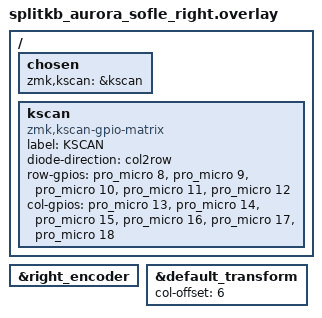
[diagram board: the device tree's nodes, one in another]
/*
 * Copyright (c) 2023 The ZMK Contributors
 *
 * SPDX-License-Identifier: MIT
 */

#include "splitkb_aurora_sofle.dtsi"

/ {
    chosen {
        zmk,kscan = &kscan;
    };

    kscan: kscan {
        compatible = "zmk,kscan-gpio-matrix";

        label = "KSCAN";
        diode-direction = "col2row";

        row-gpios
            = <&pro_micro 8 (GPIO_PULL_DOWN | GPIO_ACTIVE_HIGH)>
            , <&pro_micro 9 (GPIO_PULL_DOWN | GPIO_ACTIVE_HIGH)>
            , <&pro_micro 10 (GPIO_PULL_DOWN | GPIO_ACTIVE_HIGH)>
            , <&pro_micro 11 (GPIO_PULL_DOWN | GPIO_ACTIVE_HIGH)>
            , <&pro_micro 12 (GPIO_PULL_DOWN | GPIO_ACTIVE_HIGH)>
            ;

        col-gpios
            = <&pro_micro 13 GPIO_ACTIVE_HIGH>
            , <&pro_micro 14 GPIO_ACTIVE_HIGH>
            , <&pro_micro 15 GPIO_ACTIVE_HIGH>
            , <&pro_micro 16 GPIO_ACTIVE_HIGH>
            , <&pro_micro 17 GPIO_ACTIVE_HIGH>
            , <&pro_micro 18 GPIO_ACTIVE_HIGH>
            ;
    };
};

&right_encoder {
    status = "okay";
};

&default_transform {
    col-offset = <6>;
};
